VERSION ""

NS_ :

BS_:

BU_: PLEX

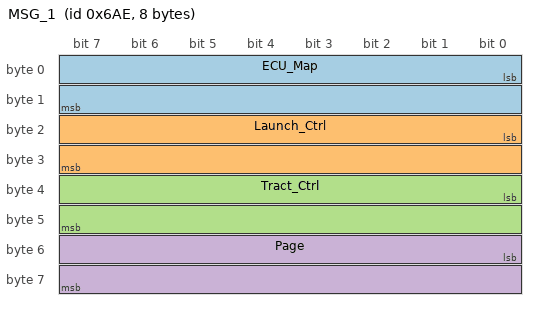
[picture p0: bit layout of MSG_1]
BO_ 1710 MSG_1: 8 PLEX
 SG_ ECU_Map : 0|16@1- (1,0) [0|0] "" Vector__XXX
 SG_ Launch_Ctrl : 16|16@1- (1,0) [0|0] "" Vector__XXX
 SG_ Tract_Ctrl : 32|16@1- (1,0) [0|0] "" Vector__XXX
 SG_ Page : 48|16@1- (1,0) [0|0] "" Vector__XXX
